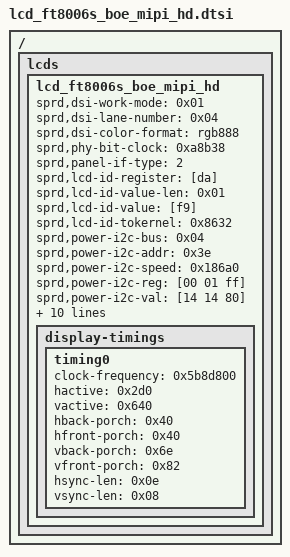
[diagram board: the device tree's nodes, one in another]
/ { lcds {
	lcd_ft8006s_boe_mipi_hd: lcd_ft8006s_boe_mipi_hd {

		sprd,dsi-work-mode = <0x01>; /* video burst mode*/
		sprd,dsi-lane-number = <0x04>;
		sprd,dsi-color-format = "rgb888";

		sprd,phy-bit-clock = <0xa8b38>;	/* kbps */

		/* panel interface type: 2:MIPI; 3:SPI */
		sprd,panel-if-type = <2>;

		/*----Id register ----*/
		sprd,lcd-id-register = [da];
		sprd,lcd-id-value-len = <0x01>;
		sprd,lcd-id-value = [f9];
		sprd,lcd-id-tokernel = <0x8632>;

		/*---Bias Power---*/
		sprd,power-i2c-bus = <0x04>;
		sprd,power-i2c-addr = <0x3e>;
		sprd,power-i2c-speed = <0x186a0>;
		sprd,power-i2c-reg = [00 01 ff];
		sprd,power-i2c-val = [14 14 80];

		sprd,reset-on-sequence = <0x01 0x32 0x00 0x32 0x01 0x96>;
		sprd,reset-off-sequence = <0x00 0x05>;

		sprd,use-dcs-write;
		sprd,initial-command = <0x23000002 0x415a3900 0x3415a 0x24230000 0x2905a39 0x341 0x5a083900 0x580c8 0x2c110039 0x341 0x5a093900 0x118000 0x60 0xc54a0140 0xa00c8220 0x8f00339 0x1190 0x9924420a 0xe39180f0 0xc3e169d8 0x66010000 0x39000011 0xa0015555 0xa04d06 0x110d605a 0xffff03a5 0xe6390000 0x11b008c9 0x16640b00 0x110160 0xffff03 0xff343900 0x9c00c 0x3f1f9f0f 0x80039 0x341 0x5a0a3900 0x1180ff 0x848f0302 0xc162130 0x3f437644 0x84ad7139 0x1190 0x905e5846 0x3523150c 0x20c1621 0x303f4376 0x3900000e 0xa04484ad 0x71905e58 0x46352315 0xc003900 0x3415a 0xb390000 0x11800000 0x00 0xa0470000 0x00 0xb0233900 0x39015 0x390000 0x3415a0c 0x39000011 0x80ba6868 0x1b275b0 0x4006015 0x501556 0x51390000 0x11901555 0x61150060 0x15005015 0x56511555 0x61953900 0x11a0ab 0x18000500 0x5000500 0x49298452 0x1090039 0x3b0 0x3900 0x3415a 0xd390000 0x1080f0b1 0x71ef4bc0 0x805a000e 0xc01200 0xaf390000 0x3415a0e 0x3900000a 0x80ff0055 0x55329876 0x71c3900 0x3415a 0xf390000 0x1180d107 0x70c01220 0x64085251 0x58490352 0x4c4c3900 0x119068 0x68684c4c 0x7c140020 0x6c20004 0x60c4039 0x5a0 0x920004 0x39000003 0x415a1039 0x1180 0x3e7 0x1f171048 0x80aad018 0x3088418a 0x39000010 0x903928a9 0xc59a7bf0 0x77ee007 0x7e201000 0x39000003 0x415a1139 0x1180 0x49770300 0xcaf4ffa3 0x2008c406 0xa1d82418 0x39000011 0x9030c666 0xc1802115 0xcbe5d268 0x6c361d04 0x8390000 0x11a05ad8 0x8860b081 0x401a1b48 0x6303b900 0x1c803900 0x11b050 0x3000e0e1 0x100280e 0x6435555 0x55555539 0x11c0 0x95888888 0x88888808 0x84c6e381 0x200021 0x39000011 0xd0428820 0x40 0x80243204 0x41264992 0x4390000 0x11e00092 0x4009204 0x00 0x92040085 0x110c3900 0x10f000 0x400000 0x5e4a 0x55790008 0x31083900 0x3415a 0x12390000 0x11800000 0x02 0x3000000 0x20300 0x41373900 0x1190f1 0xe7000000 0x00 0x00 0x2d230539 0x8a0 0xfb082d23 0x5fb0c39 0x341 0x5a133900 0x1180fd 0xf000c00 0xa001 0x8011c44 0xccee739 0x1190 0x620e2498 0xac210100 0xd0932449 0x6188813 0x39000011 0xa0881388 0x139fb88b 0x58028813 0x88135802 0x390000 0xcb00000 0x00 0x1b 0x10390000 0x3415a14 0x39000011 0x80010241 0x36e9eff7 0xfbfd7e00 0x90c5 0x89390000 0x1190273d 0x20463ce9 0x1f1e149 0xf880d4f 0x7a003900 0x11a000 0x00 0x00 0x00 0x39 0x11b0 0x00 0x00 0x1cb221 0x2b0040a1 0x39000011 0xc0507807 0x5af29051 0x1c6f404b 0x1e328ae3 0x5390000 0x11d068c9 0x434671bc 0x22d79c8 0x288e77a1 0x250f3900 0x11e019 0xc5f126b4 0xe421a338 0xde83963c 0x6414c739 0x11f0 0x5bd09287 0x8ce21801 0xbf5f0800 0x00 0x39000003 0x415a1539 0x1180 0x00 0x00 0x00 0x52d9e0f7 0x39000011 0x90a30020 0x4b85aad5 0x6919157 0xa16ab541 0x64390000 0x11a07800 0x00 0x00 0x00 0x3900 0x11b004 0x00 0x4012 0x94 0x960c4d39 0x11c0 0xc90241c1 0x509cb66d 0xdbb66ddb 0xb66dc1d0 0x39000011 0xd0a42012 0x64100268 0xdbb66ddb 0xb66ddb96 0xc390000 0x11e04d88 0x2418040 0x98b66ddb 0xb66ddbb6 0x6dc13900 0x11f0d0 0xb4241274 0x144368db 0xb66ddbb6 0x6d5b9239 0x341 0x5a163900 0x118082 0x82820200 0x00 0x00 0x39 0x790 0x00 0xf0203900 0x3415a 0x18390000 0x118004ff 0x808000 0x4200001 0x8400002 0x10803900 0x39000 0x4390000 0x3415a19 0x39000011 0x80c0afa3 0x9b928d8a 0x86848382 0x810050f6 0xcf390000 0x1190fc2f 0xf3efcfbf 0xfffafb5 0x710e6c4a 0x69083900 0x5a000 0x460039 0x341 0x5a1a3900 0x118000 0x4080c00 0x1014181c 0x202830 0x38004039 0x1190 0x48505800 0x60687078 0x808890 0x9800a0a8 0x39000011 0xa0b0b800 0xc0c8d0d8 0xe0e8f0 0xf800fcfe 0xff390000 0x11b00000 0x4080c00 0x1014181c 0x202830 0x38003900 0x11c040 0x48505800 0x60687078 0x808890 0x9800a039 0x11d0 0xa8b0b800 0xc0c8d0d8 0xe0e8f0 0xf800fcfe 0x39000011 0xe0ff0000 0x4080c00 0x1014181c 0x202830 0x38390000 0x11f00040 0x48505800 0x60687078 0x808890 0x98003900 0x3415a 0x1b390000 0x1180a0a8 0xb0b800c0 0xc8d0d800 0xe0e8f0f8 0xfc3900 0x590fe 0xff000039 0x341 0x5a203900 0x88084 0x21400 0x3900 0x3415a 0x22390000 0xe802dd3 0x555555 0x55555555 0x559f0039 0x341 0x5a233900 0x118000 0x500 0x00 0x00 0x39 0xd90 0xff0f0000 0x30000 0xff0735 0x39000003 0x415a2439 0x1180 0x300ff 0xff200000 0x00 0x3c57 0x39000011 0x905a5a5a 0x55000000 0x00 0x00 0x230000 0x2422423 0x290 0x390000 0x3415a2f 0x23000002 0x19012300 0x24c03 0x23000002 0x55002300 0x23500 0x23780002 0x11002300 0x29009 0x23000002 0x9101230a 0x22900>;
		sprd,sleep-in-command = <0x23140002 0x28002332 0x21000 0x23000002 0x175a2360 0x2185a>;
		sprd,sleep-out-command = <0x23780023 0x11002314 0x232900>;

		display-timings {
			timing0 {
				clock-frequency = <0x5b8d800>;
				hactive = <0x2d0>;
				vactive = <0x640>;
				hback-porch = <0x40>;
				hfront-porch = <0x40>;
				vback-porch = <0x6e>;
				vfront-porch = <0x82>;
				hsync-len = <0x0e>;
				vsync-len = <0x08>;
			};
		};
	};
};};
